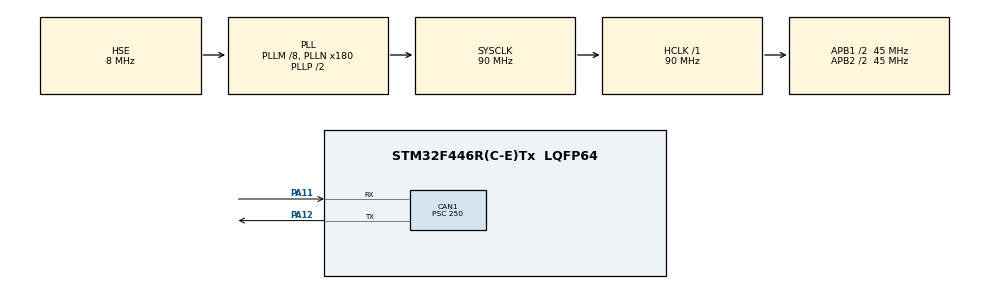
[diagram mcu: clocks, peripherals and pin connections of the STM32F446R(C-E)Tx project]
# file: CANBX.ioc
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CAN1.BS1=CAN_BS1_15TQ
CAN1.BS2=CAN_BS2_2TQ
CAN1.CalculateBaudRate=10000
CAN1.CalculateTimeBit=100000
CAN1.CalculateTimeQuantum=5555.555555555556
CAN1.Mode=CAN_MODE_NORMAL
CAN1.Prescaler=250
CAN1.RFLM=ENABLE
Mcu.Family=STM32F4
Mcu.Name=STM32F446R(C-E)Tx
Mcu.Package=LQFP64
NVIC.PriorityGroup=NVIC_PRIORITYGROUP_0
PA11.GPIO_PuPd=GPIO_PULLUP
PA11.Mode=CAN_Activate
PA11.Signal=CAN1_RX
PA12.Mode=CAN_Activate
PA12.Signal=CAN1_TX
PH0-OSC_IN.Mode=HSE-External-Oscillator
PH0-OSC_IN.Signal=RCC_OSC_IN
PH1-OSC_OUT.Mode=HSE-External-Oscillator
PH1-OSC_OUT.Signal=RCC_OSC_OUT
ProjectManager.HeapSize=0x200
ProjectManager.StackSize=0x400
ProjectManager.TargetToolchain=STM32CubeIDE
RCC.48MHZClocksFreq_Value=84000000
RCC.AHBFreq_Value=90000000
RCC.APB1CLKDivider=RCC_HCLK_DIV2
RCC.APB1Freq_Value=45000000
RCC.APB1TimFreq_Value=90000000
RCC.APB2CLKDivider=RCC_HCLK_DIV2
RCC.APB2Freq_Value=45000000
RCC.APB2TimFreq_Value=90000000
RCC.CortexFreq_Value=90000000
RCC.FLatency-AdvancedSettings=FLASH_LATENCY_2
RCC.HCLKFreq_Value=90000000
RCC.HSE_VALUE=8000000
RCC.HSI_VALUE=16000000
RCC.PLLM=8
RCC.PLLN=180
RCC.PLLSourceVirtual=RCC_PLLSOURCE_HSE
RCC.SYSCLKFreq_VALUE=90000000
RCC.SYSCLKSource=RCC_SYSCLKSOURCE_PLLCLK
RCC.USBFreq_Value=90000000
RCC.VCOOutputFreq_Value=180000000
board=NUCLEO-F446RE

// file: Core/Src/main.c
/* USER CODE BEGIN Header */
/**
  ******************************************************************************
  * @file           : main.c
  * @brief          : Main program body
  ******************************************************************************
  * @attention
  *
  * Copyright (c) 2024 STMicroelectronics.
  * All rights reserved.
  *
  * This software is licensed under terms that can be found in the LICENSE file
  * in the root directory of this software component.
  * If no LICENSE file comes with this software, it is provided AS-IS.
  *
  ******************************************************************************
  */
/* USER CODE END Header */
#include "main.h"

/* USER CODE BEGIN PD */
	uint8_t  rcv_data[1];

/* USER CODE END PD */

CAN_HandleTypeDef hcan1;

void SystemClock_Config(void);
static void MX_GPIO_Init(void);
static void MX_CAN1_Init(void);
/* USER CODE BEGIN PFP */
void CAN_Filtering_Config(void);
void CAN_RX();
/* USER CODE END PFP */

int main(void)
{

  /* MCU Configuration--------------------------------------------------------*/

  /* Reset of all peripherals, Initializes the Flash interface and the Systick. */
  HAL_Init();

  /* Configure the system clock */
  SystemClock_Config();

  /* Initialize all configured peripherals */
  MX_GPIO_Init();
  MX_CAN1_Init();
  /* USER CODE BEGIN 2 */
  CAN_Filtering_Config();
  HAL_CAN_Start(&hcan1);
  /* USER CODE END 2 */

  /* Infinite loop */
  while (1)
  {

    /* USER CODE BEGIN 3 */
	    CAN_RX();
	      /*CAN_TxHeaderTypeDef txHeader;
	      uint32_t txMailbox;
	      uint8_t txData[1] = {123}; // Données à envoyer

	      // Configuration de l'en-tête du message CAN
	      txHeader.StdId = 0X65; // ID du message CAN
	      txHeader.ExtId = 0;     // ID étendu, pas utilisé dans ce cas
	      txHeader.IDE = CAN_ID_STD; // Format de l'ID :
	      txHeader.RTR = CAN_RTR_DATA; // Type de trame : données
	      txHeader.DLC = 1; // Longueur des données à envoyer

	      // Envoi du message CAN
	      if (HAL_CAN_AddTxMessage(&hcan1, &txHeader, txData, &txMailbox) != HAL_OK)
	      {
	        Error_Handler();
	      }

	      // Attente de 1 seconde
	      HAL_Delay(1000);*/

  }
  /* USER CODE END 3 */
}

void SystemClock_Config(void)
{
  RCC_OscInitTypeDef RCC_OscInitStruct = {0};
  RCC_ClkInitTypeDef RCC_ClkInitStruct = {0};

  /** Configure the main internal regulator output voltage
  */
  __HAL_RCC_PWR_CLK_ENABLE();
  __HAL_PWR_VOLTAGESCALING_CONFIG(PWR_REGULATOR_VOLTAGE_SCALE3);

  /** Initializes the RCC Oscillators according to the specified parameters
  * in the RCC_OscInitTypeDef structure.
  */
  RCC_OscInitStruct.OscillatorType = RCC_OSCILLATORTYPE_HSE;
  RCC_OscInitStruct.HSEState = RCC_HSE_ON;
  RCC_OscInitStruct.PLL.PLLState = RCC_PLL_ON;
  RCC_OscInitStruct.PLL.PLLSource = RCC_PLLSOURCE_HSE;
  RCC_OscInitStruct.PLL.PLLM = 8;
  RCC_OscInitStruct.PLL.PLLN = 180;
  RCC_OscInitStruct.PLL.PLLP = RCC_PLLP_DIV2;
  RCC_OscInitStruct.PLL.PLLQ = 2;
  RCC_OscInitStruct.PLL.PLLR = 2;
  if (HAL_RCC_OscConfig(&RCC_OscInitStruct) != HAL_OK)
  {
    Error_Handler();
  }

  /** Initializes the CPU, AHB and APB buses clocks
  */
  RCC_ClkInitStruct.ClockType = RCC_CLOCKTYPE_HCLK|RCC_CLOCKTYPE_SYSCLK
                              |RCC_CLOCKTYPE_PCLK1|RCC_CLOCKTYPE_PCLK2;
  RCC_ClkInitStruct.SYSCLKSource = RCC_SYSCLKSOURCE_PLLCLK;
  RCC_ClkInitStruct.AHBCLKDivider = RCC_SYSCLK_DIV1;
  RCC_ClkInitStruct.APB1CLKDivider = RCC_HCLK_DIV2;
  RCC_ClkInitStruct.APB2CLKDivider = RCC_HCLK_DIV2;

  if (HAL_RCC_ClockConfig(&RCC_ClkInitStruct, FLASH_LATENCY_2) != HAL_OK)
  {
    Error_Handler();
  }
}

static void MX_CAN1_Init(void)
{

  hcan1.Instance = CAN1;
  hcan1.Init.Prescaler = 250;
  hcan1.Init.Mode = CAN_MODE_NORMAL;
  hcan1.Init.SyncJumpWidth = CAN_SJW_1TQ;
  hcan1.Init.TimeSeg1 = CAN_BS1_15TQ;
  hcan1.Init.TimeSeg2 = CAN_BS2_2TQ;
  hcan1.Init.TimeTriggeredMode = DISABLE;
  hcan1.Init.AutoBusOff = DISABLE;
  hcan1.Init.AutoWakeUp = DISABLE;
  hcan1.Init.AutoRetransmission = DISABLE;
  hcan1.Init.ReceiveFifoLocked = ENABLE;
  hcan1.Init.TransmitFifoPriority = DISABLE;
  if (HAL_CAN_Init(&hcan1) != HAL_OK)
  {
    Error_Handler();
  }

}

static void MX_GPIO_Init(void)
{

  /* GPIO Ports Clock Enable */
  __HAL_RCC_GPIOH_CLK_ENABLE();
  __HAL_RCC_GPIOA_CLK_ENABLE();

}

/* USER CODE BEGIN 4 */
void CAN_Filtering_Config(void)
{
	CAN_FilterTypeDef CAN_filter_init;
	CAN_filter_init.FilterActivation=CAN_FILTER_ENABLE;
	CAN_filter_init.FilterBank=0;
	CAN_filter_init.FilterFIFOAssignment=CAN_RX_FIFO0;
	CAN_filter_init.FilterIdHigh=0x00000000;
	CAN_filter_init.FilterIdLow=0x00000000;
	CAN_filter_init.FilterMaskIdHigh=0x00000000;
	CAN_filter_init.FilterMaskIdLow=0x00000000;
	CAN_filter_init.FilterMode=CAN_FILTERMODE_IDMASK;
	CAN_filter_init.FilterScale=CAN_FILTERSCALE_32BIT;
	if(HAL_CAN_ConfigFilter(&hcan1, &CAN_filter_init)!=HAL_OK){
		Error_Handler();
	}

}
void CAN_RX(){

	CAN_RxHeaderTypeDef Rxheader;
	while(! HAL_CAN_GetRxFifoFillLevel(&hcan1, CAN_RX_FIFO0));
	HAL_CAN_GetRxMessage(&hcan1, CAN_RX_FIFO0, &Rxheader, rcv_data);
	HAL_Delay(1000);

}
/* USER CODE END 4 */

void Error_Handler(void)
{
  __disable_irq();
  while (1)
  {
  }
}
